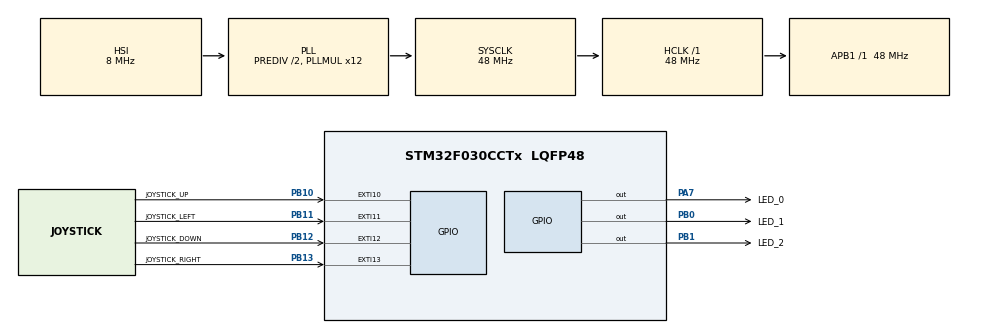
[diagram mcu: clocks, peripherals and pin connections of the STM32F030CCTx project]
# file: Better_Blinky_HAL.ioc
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Mcu.Family=STM32F0
Mcu.Name=STM32F030CCTx
Mcu.Package=LQFP48
NVIC.EXTI4_15_IRQn=true\:0\:0\:false\:false\:true\:true\:true\:true
NVIC.TIM3_IRQn=true\:0\:0\:false\:false\:true\:true\:true\:true
PA7.GPIO_Label=LED_0
PA7.Signal=GPIO_Output
PB0.GPIO_Label=LED_1
PB0.Signal=GPIO_Output
PB1.GPIO_Label=LED_2
PB1.Signal=GPIO_Output
PB10.GPIO_Label=JOYSTICK_UP
PB10.GPIO_ModeDefaultEXTI=GPIO_MODE_IT_FALLING
PB10.Signal=GPXTI10
PB11.GPIO_Label=JOYSTICK_LEFT
PB11.GPIO_ModeDefaultEXTI=GPIO_MODE_IT_FALLING
PB11.Signal=GPXTI11
PB12.GPIO_Label=JOYSTICK_DOWN
PB12.GPIO_ModeDefaultEXTI=GPIO_MODE_IT_FALLING
PB12.Signal=GPXTI12
PB13.GPIO_Label=JOYSTICK_RIGHT
PB13.GPIO_ModeDefaultEXTI=GPIO_MODE_IT_FALLING
PB13.Signal=GPXTI13
ProjectManager.HeapSize=0x200
ProjectManager.StackSize=0x400
ProjectManager.TargetToolchain=STM32CubeIDE
RCC.AHBFreq_Value=48000000
RCC.APB1Freq_Value=48000000
RCC.APB1TimFreq_Value=48000000
RCC.HCLKFreq_Value=48000000
RCC.PLLDivider=RCC_PREDIV_DIV2
RCC.PLLMUL=RCC_PLL_MUL12
RCC.SYSCLKFreq_VALUE=48000000
RCC.SYSCLKSource=RCC_SYSCLKSOURCE_PLLCLK
TIM3.AutoReloadPreload=TIM_AUTORELOAD_PRELOAD_DISABLE
TIM3.Period=DEFAULT_PERIOD_MS - 1
TIM3.Prescaler=48000 - 1
VP_TIM3_VS_ClockSourceINT.Mode=Internal
board=custom

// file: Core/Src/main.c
/* USER CODE BEGIN Header */
/**
  ******************************************************************************
  * @file           : main.c
  * @brief          : Main program body
  ******************************************************************************
  * @attention
  *
  * Copyright (c) 2024 STMicroelectronics.
  * All rights reserved.
  *
  * This software is licensed under terms that can be found in the LICENSE file
  * in the root directory of this software component.
  * If no LICENSE file comes with this software, it is provided AS-IS.
  *
  ******************************************************************************
  */
/* USER CODE END Header */
#include "main.h"
#include "blink_led.h"

TIM_HandleTypeDef htim3;

void SystemClock_Config(void);
static void MX_GPIO_Init(void);
static void MX_TIM3_Init(void);

int main(void)
{

    /* MCU Configuration--------------------------------------------------------*/

    /* Reset of all peripherals, Initializes the Flash interface and the Systick. */
    HAL_Init();

    /* Configure the system clock */
    SystemClock_Config();

    /* Initialize all configured peripherals */
    MX_GPIO_Init();
    MX_TIM3_Init();
    /* USER CODE BEGIN 2 */
    initialise();
    /* USER CODE END 2 */

    /* Infinite loop */
    while (1)
    {

    }
}

void SystemClock_Config(void)
{
    RCC_OscInitTypeDef RCC_OscInitStruct = {0};
    RCC_ClkInitTypeDef RCC_ClkInitStruct = {0};

    /** Initializes the RCC Oscillators according to the specified parameters
    * in the RCC_OscInitTypeDef structure.
    */
    RCC_OscInitStruct.OscillatorType = RCC_OSCILLATORTYPE_HSI;
    RCC_OscInitStruct.HSIState = RCC_HSI_ON;
    RCC_OscInitStruct.HSICalibrationValue = RCC_HSICALIBRATION_DEFAULT;
    RCC_OscInitStruct.PLL.PLLState = RCC_PLL_ON;
    RCC_OscInitStruct.PLL.PLLSource = RCC_PLLSOURCE_HSI;
    RCC_OscInitStruct.PLL.PLLMUL = RCC_PLL_MUL12;
    RCC_OscInitStruct.PLL.PREDIV = RCC_PREDIV_DIV2;
    if (HAL_RCC_OscConfig(&RCC_OscInitStruct) != HAL_OK)
    {
        Error_Handler();
    }

    /** Initializes the CPU, AHB and APB buses clocks
    */
    RCC_ClkInitStruct.ClockType = RCC_CLOCKTYPE_HCLK | RCC_CLOCKTYPE_SYSCLK
        | RCC_CLOCKTYPE_PCLK1;
    RCC_ClkInitStruct.SYSCLKSource = RCC_SYSCLKSOURCE_PLLCLK;
    RCC_ClkInitStruct.AHBCLKDivider = RCC_SYSCLK_DIV1;
    RCC_ClkInitStruct.APB1CLKDivider = RCC_HCLK_DIV1;

    if (HAL_RCC_ClockConfig(&RCC_ClkInitStruct, FLASH_LATENCY_1) != HAL_OK)
    {
        Error_Handler();
    }
}

static void MX_TIM3_Init(void)
{

    TIM_ClockConfigTypeDef sClockSourceConfig = {0};
    TIM_MasterConfigTypeDef sMasterConfig = {0};

    htim3.Instance = TIM3;
    htim3.Init.Prescaler = 48000 - 1;
    htim3.Init.CounterMode = TIM_COUNTERMODE_UP;
    htim3.Init.Period = DEFAULT_PERIOD_MS - 1;
    htim3.Init.ClockDivision = TIM_CLOCKDIVISION_DIV1;
    htim3.Init.AutoReloadPreload = TIM_AUTORELOAD_PRELOAD_DISABLE;
    if (HAL_TIM_Base_Init(&htim3) != HAL_OK)
    {
        Error_Handler();
    }
    sClockSourceConfig.ClockSource = TIM_CLOCKSOURCE_INTERNAL;
    if (HAL_TIM_ConfigClockSource(&htim3, &sClockSourceConfig) != HAL_OK)
    {
        Error_Handler();
    }
    sMasterConfig.MasterOutputTrigger = TIM_TRGO_RESET;
    sMasterConfig.MasterSlaveMode = TIM_MASTERSLAVEMODE_DISABLE;
    if (HAL_TIMEx_MasterConfigSynchronization(&htim3, &sMasterConfig) != HAL_OK)
    {
        Error_Handler();
    }
    /* USER CODE BEGIN TIM3_Init 2 */

    __HAL_TIM_URS_ENABLE(&htim3);  // Enable URS bit analoguous to the bare-metal better-blinky.c

    /* USER CODE END TIM3_Init 2 */
}

static void MX_GPIO_Init(void)
{
    GPIO_InitTypeDef GPIO_InitStruct = {0};

    /* GPIO Ports Clock Enable */
    __HAL_RCC_GPIOA_CLK_ENABLE();
    __HAL_RCC_GPIOB_CLK_ENABLE();

    /*Configure GPIO pin Output Level */
    HAL_GPIO_WritePin(LED_0_GPIO_Port, LED_0_Pin, GPIO_PIN_RESET);

    /*Configure GPIO pin Output Level */
    HAL_GPIO_WritePin(GPIOB, LED_1_Pin | LED_2_Pin, GPIO_PIN_RESET);

    /*Configure GPIO pin : LED_0_Pin */
    GPIO_InitStruct.Pin = LED_0_Pin;
    GPIO_InitStruct.Mode = GPIO_MODE_OUTPUT_PP;
    GPIO_InitStruct.Pull = GPIO_NOPULL;
    GPIO_InitStruct.Speed = GPIO_SPEED_FREQ_LOW;
    HAL_GPIO_Init(LED_0_GPIO_Port, &GPIO_InitStruct);

    /*Configure GPIO pins : LED_1_Pin LED_2_Pin */
    GPIO_InitStruct.Pin = LED_1_Pin | LED_2_Pin;
    GPIO_InitStruct.Mode = GPIO_MODE_OUTPUT_PP;
    GPIO_InitStruct.Pull = GPIO_NOPULL;
    GPIO_InitStruct.Speed = GPIO_SPEED_FREQ_LOW;
    HAL_GPIO_Init(GPIOB, &GPIO_InitStruct);

    /*Configure GPIO pins : JOYSTICK_UP_Pin JOYSTICK_LEFT_Pin JOYSTICK_DOWN_Pin JOYSTICK_RIGHT_Pin */
    GPIO_InitStruct.Pin = JOYSTICK_UP_Pin | JOYSTICK_LEFT_Pin | JOYSTICK_DOWN_Pin | JOYSTICK_RIGHT_Pin;
    GPIO_InitStruct.Mode = GPIO_MODE_IT_FALLING;
    GPIO_InitStruct.Pull = GPIO_NOPULL;
    HAL_GPIO_Init(GPIOB, &GPIO_InitStruct);

    /* EXTI interrupt init*/
    HAL_NVIC_SetPriority(EXTI4_15_IRQn, 0, 0);
    HAL_NVIC_EnableIRQ(EXTI4_15_IRQn);

}

void Error_Handler(void)
{
    /* USER CODE BEGIN Error_Handler_Debug */
    /* User can add his own implementation to report the HAL error return state */
    __disable_irq();
    while (1)
    {
        // blink the first led if an error occurs
        HAL_GPIO_TogglePin(LED_0_GPIO_Port, LED_0_Pin);
        HAL_Delay(200);
    }
    /* USER CODE END Error_Handler_Debug */
}
